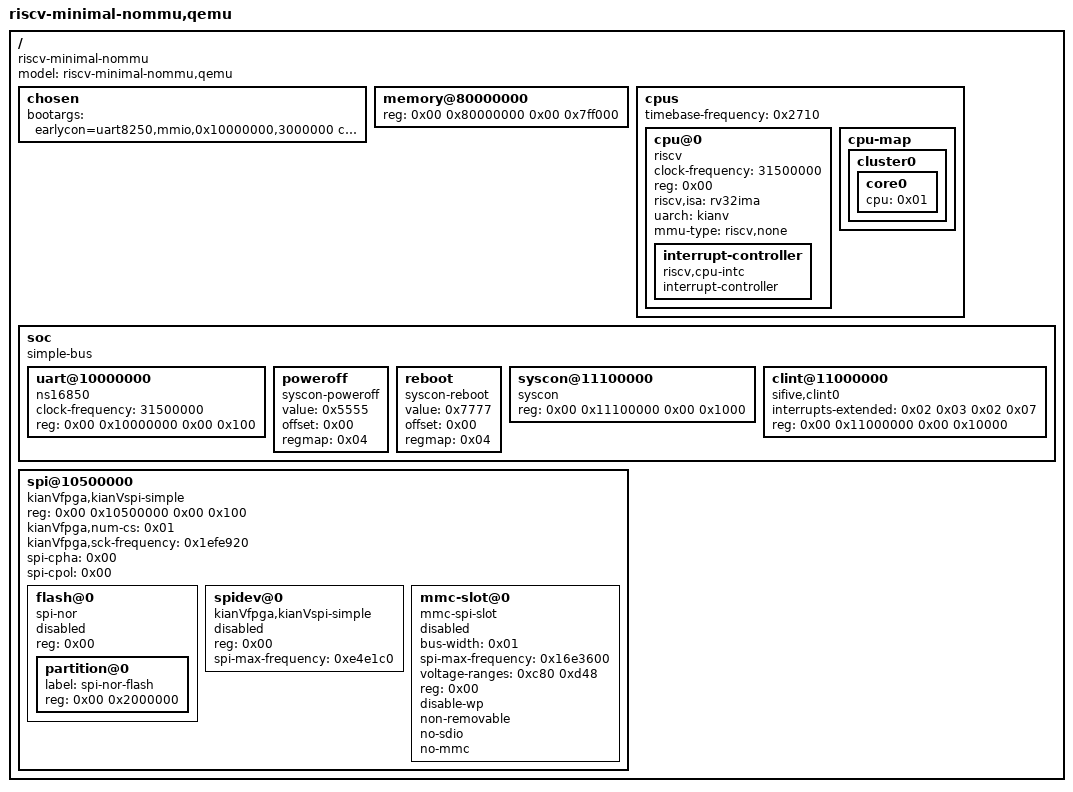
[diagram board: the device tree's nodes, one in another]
/dts-v1/;

/ {
	#address-cells = <0x02>;
	#size-cells = <0x02>;
	compatible = "riscv-minimal-nommu";
	model = "riscv-minimal-nommu,qemu";

	chosen {
		bootargs = "earlycon=uart8250,mmio,0x10000000,3000000 console=ttyS0 debug";
	};

	memory@80000000 {
		device_type = "memory";
		reg = <0x00 0x80000000 0x00 0x7ff000>;
	};

	cpus {
		#address-cells = <0x01>;
		#size-cells = <0x00>;
		timebase-frequency = <0x2710>;

		cpu@0 {
			clock-frequency = <31500000>;
			phandle = <0x01>;
			device_type = "cpu";
			reg = <0x00>;
			status = "okay";
			compatible = "riscv";
			riscv,isa = "rv32ima";
			uarch = "kianv";
			mmu-type = "riscv,none";

			interrupt-controller {
				#interrupt-cells = <0x01>;
				interrupt-controller;
				compatible = "riscv,cpu-intc";
				phandle = <0x02>;
			};
		};

		cpu-map {

			cluster0 {

				core0 {
					cpu = <0x01>;
				};
			};
		};
	};

	soc {
		#address-cells = <0x02>;
		#size-cells = <0x02>;
		compatible = "simple-bus";
		ranges;

		uart@10000000 {
			device_type = "serial";
			clock-frequency = <31500000>;
			reg = <0x00 0x10000000 0x00 0x100>;
			compatible = "ns16850";
		};

		poweroff {
			value = <0x5555>;
			offset = <0x00>;
			regmap = <0x04>;
			compatible = "syscon-poweroff";
		};

		reboot {
			value = <0x7777>;
			offset = <0x00>;
			regmap = <0x04>;
			compatible = "syscon-reboot";
		};

		syscon@11100000 {
			phandle = <0x04>;
			reg = <0x00 0x11100000 0x00 0x1000>;
			compatible = "syscon";
		};

		clint@11000000 {
			interrupts-extended = <0x02 0x03 0x02 0x07>;
			reg = <0x00 0x11000000 0x00 0x10000>;
			compatible = "sifive,clint0\0riscv,clint0";
		};
	};

	spi@10500000 {
		compatible = "kianVfpga,kianVspi-simple";
		reg = <0x00 0x10500000 0x00 0x100>;
		kianVfpga,num-cs = <0x01>;
		kianVfpga,sck-frequency = <0x1efe920>;
		spi-cpha = <0x00>;
		spi-cpol = <0x00>;
		#address-cells = <0x01>;
		#size-cells = <0x00>;

		flash@0 {
			compatible = "spi-nor";
			status = "disabled";
			reg = <0x00>;
			#address-cells = <0x01>;
			#size-cells = <0x01>;

			partition@0 {
				label = "spi-nor-flash";
				reg = <0x00 0x2000000>;
			};
		};

		spidev@0 {
			compatible = "kianVfpga,kianVspi-simple";
			reg = <0x00>;
			spi-max-frequency = <0xe4e1c0>;
			status = "disabled";
		};

		mmc-slot@0 {
			compatible = "mmc-spi-slot";
			bus-width = <0x01>;
			spi-max-frequency = <0x16e3600>;
			voltage-ranges = <0xc80 0xd48>;
			reg = <0x00>;
			status = "disabled";
			disable-wp;
			non-removable;
			no-sdio;
			no-mmc;
		};
	};
};
